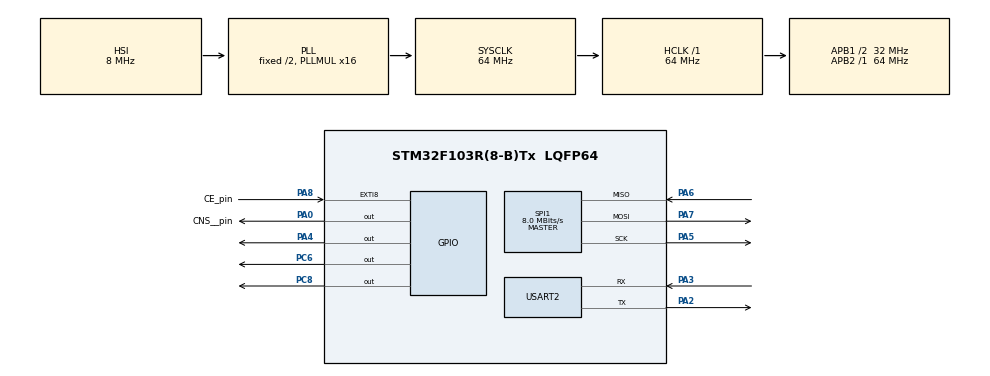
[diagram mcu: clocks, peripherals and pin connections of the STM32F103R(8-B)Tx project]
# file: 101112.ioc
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Mcu.Family=STM32F1
Mcu.Name=STM32F103R(8-B)Tx
Mcu.Package=LQFP64
NVIC.EXTI9_5_IRQn=true\:0\:0\:false\:false\:true\:true\:true\:true
NVIC.PriorityGroup=NVIC_PRIORITYGROUP_4
NVIC.USART2_IRQn=true\:0\:0\:false\:false\:true\:true\:true\:true
PA0-WKUP.GPIO_Label=CNS__pin
PA0-WKUP.Signal=GPIO_Output
PA2.Mode=Asynchronous
PA2.Signal=USART2_TX
PA3.Mode=Asynchronous
PA3.Signal=USART2_RX
PA4.Signal=GPIO_Output
PA5.Mode=Full_Duplex_Master
PA5.Signal=SPI1_SCK
PA6.Mode=Full_Duplex_Master
PA6.Signal=SPI1_MISO
PA7.Mode=Full_Duplex_Master
PA7.Signal=SPI1_MOSI
PA8.GPIO_Label=CE_pin
PA8.Signal=GPXTI8
PC6.Signal=GPIO_Output
PC8.Signal=GPIO_Output
ProjectManager.HeapSize=0x200
ProjectManager.StackSize=0x400
ProjectManager.TargetToolchain=STM32CubeIDE
RCC.AHBFreq_Value=64000000
RCC.APB1CLKDivider=RCC_HCLK_DIV2
RCC.APB1Freq_Value=32000000
RCC.APB1TimFreq_Value=64000000
RCC.APB2Freq_Value=64000000
RCC.APB2TimFreq_Value=64000000
RCC.HCLKFreq_Value=64000000
RCC.PLLMUL=RCC_PLL_MUL16
RCC.RTCClockSelection=RCC_RTCCLKSOURCE_LSE
RCC.SYSCLKFreq_VALUE=64000000
RCC.SYSCLKSource=RCC_SYSCLKSOURCE_PLLCLK
RCC.USBFreq_Value=64000000
SPI1.BaudRatePrescaler=SPI_BAUDRATEPRESCALER_8
SPI1.CalculateBaudRate=8.0 MBits/s
SPI1.Direction=SPI_DIRECTION_2LINES
SPI1.Mode=SPI_MODE_MASTER
SPI1.VirtualType=VM_MASTER
USART2.VirtualMode=VM_ASYNC
VP_SYS_VS_ND.Mode=No_Debug
board=NUCLEO-F103RB

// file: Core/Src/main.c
/* USER CODE BEGIN Header */
/**
  ******************************************************************************
  * @file           : main.c
  * @brief          : Main program body
  ******************************************************************************
  * @attention
  *
  * Copyright (c) 2025 STMicroelectronics.
  * All rights reserved.
  *
  * This software is licensed under terms that can be found in the LICENSE file
  * in the root directory of this software component.
  * If no LICENSE file comes with this software, it is provided AS-IS.
  *
  ******************************************************************************
  */
/* USER CODE END Header */
#include "main.h"
#include "spi.h"
#include "usart.h"
#include "gpio.h"

/* USER CODE BEGIN Includes */
#include "nrf24l01p.h"
#include <string.h>
#include "stdio.h"

/* USER CODE END Includes */

/* USER CODE BEGIN PV */

//uint8_t rx_payload[NRF24L01P_PAYLOAD_LENGTH];

/* USER CODE END PV */

void SystemClock_Config(void);

/* USER CODE BEGIN 0 */

uint8_t rx_data[32];  // 수신할 데이터를 저장할 배열
uint8_t addr[5] = {'R','x','A','A','A'};  // 송수신 주소 설정

//uint8_t rx_payload[NRF24L01P_PAYLOAD_LENGTH];

int main(void)
{

  /* USER CODE BEGIN 1 */
	 HAL_Init();

	   write_register_multi(NRF24L01P_REG_RX_ADDR_P0, addr, 5);
  /* USER CODE END 1 */

  /* MCU Configuration--------------------------------------------------------*/

  /* Reset of all peripherals, Initializes the Flash interface and the Systick. */

  /* USER CODE BEGIN Init */
	   SystemClock_Config();
	   MX_GPIO_Init();
	       MX_SPI1_Init();
	       MX_USART2_UART_Init();  // UART 초기화

	       nrf24l01p_rx_init(2, _1Mbps);  // 채널 2402MHz,
	       write_register_multi(NRF24L01P_REG_RX_ADDR_P0, addr, 5);
  /* USER CODE END Init */

  /* Configure the system clock */

  /* Initialize all configured peripherals */

  /* Infinite loop */
  while (1)
  {
	  HAL_UART_Receive(&huart2, rx_data, sizeof(rx_data), HAL_MAX_DELAY);  // UART2에서 데이터 수신

	      /* 수신된 데이터가 비어 있지 않으면 LED 켜기 */
	      if (rx_data[0] != '\0')
	      {
	          /* PC8번 LED 켜기 */
	          HAL_GPIO_WritePin(GPIOC, GPIO_PIN_8, GPIO_PIN_SET);

	          /* 수신된 데이터 출력 */
	          printf("Received: %s\n", rx_data);  // 수신된 데이터를 터미널에 출력

	          /* PC6번 LED 켜기 */
	          HAL_GPIO_WritePin(GPIOC, GPIO_PIN_6, GPIO_PIN_SET);
	      }

	          HAL_GPIO_WritePin(GPIOC, GPIO_PIN_6, GPIO_PIN_RESET);

	      /* 1초 대기 */
	      HAL_Delay(1000);
  }
}
int __io_putchar(int ch)
{
    HAL_UART_Transmit(&huart2, (uint8_t*)&ch, 1, HAL_MAX_DELAY);  // UART2로 데이터 전송
    return ch;
}
void SystemClock_Config(void)
{
  RCC_OscInitTypeDef RCC_OscInitStruct = {0};
  RCC_ClkInitTypeDef RCC_ClkInitStruct = {0};

  /** Initializes the RCC Oscillators according to the specified parameters
  * in the RCC_OscInitTypeDef structure.
  */
  RCC_OscInitStruct.OscillatorType = RCC_OSCILLATORTYPE_HSI;
  RCC_OscInitStruct.HSIState = RCC_HSI_ON;
  RCC_OscInitStruct.HSICalibrationValue = RCC_HSICALIBRATION_DEFAULT;
  RCC_OscInitStruct.PLL.PLLState = RCC_PLL_ON;
  RCC_OscInitStruct.PLL.PLLSource = RCC_PLLSOURCE_HSI_DIV2;
  RCC_OscInitStruct.PLL.PLLMUL = RCC_PLL_MUL16;
  if (HAL_RCC_OscConfig(&RCC_OscInitStruct) != HAL_OK)
  {
    Error_Handler();
  }

  /** Initializes the CPU, AHB and APB buses clocks
  */
  RCC_ClkInitStruct.ClockType = RCC_CLOCKTYPE_HCLK|RCC_CLOCKTYPE_SYSCLK
                              |RCC_CLOCKTYPE_PCLK1|RCC_CLOCKTYPE_PCLK2;
  RCC_ClkInitStruct.SYSCLKSource = RCC_SYSCLKSOURCE_PLLCLK;
  RCC_ClkInitStruct.AHBCLKDivider = RCC_SYSCLK_DIV1;
  RCC_ClkInitStruct.APB1CLKDivider = RCC_HCLK_DIV2;
  RCC_ClkInitStruct.APB2CLKDivider = RCC_HCLK_DIV1;

  if (HAL_RCC_ClockConfig(&RCC_ClkInitStruct, FLASH_LATENCY_2) != HAL_OK)
  {
    Error_Handler();
  }

}

void Error_Handler(void)
{
  __disable_irq();
  while (1)
  {
  }
}
